# NSUC1602 register map
Vendor: ARM Ltd.; Series: NSUC1602; File version: 0.0
CPU: CM3 r1p0, little endian, MPU, no FPU, 3 interrupt priority bits
Registers are 32-bit, read-write, reset 0x0 unless marked. A register's access mark holds for its fields unless they carry their own. Offsets are from the block's base; [hi:lo] are bit positions; {n}, {i} and the like mark numbered series.

## GDU — S/T bus
Base 0x40000000
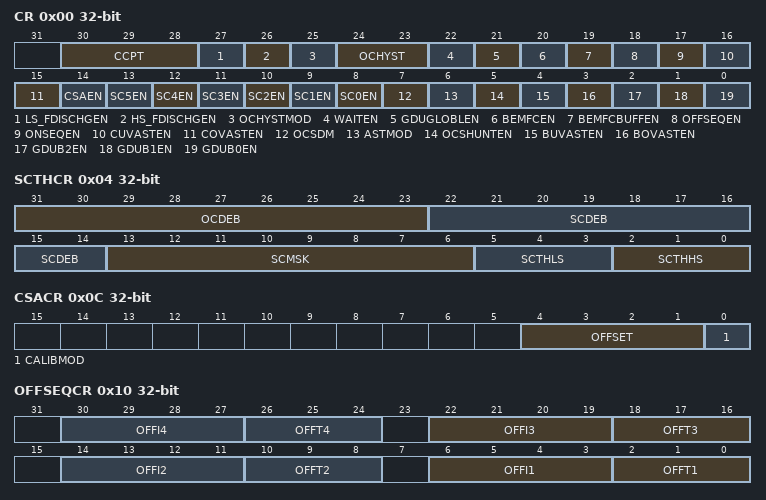
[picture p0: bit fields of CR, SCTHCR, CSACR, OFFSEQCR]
0x00 CR (reset mask 0x1337F7F) — GDU控制寄存器
  [30:28] CCPT, [27] LS_FDISCHGEN, [26] HS_FDISCHGEN, [25] OCHYSTMOD, [24:23] OCHYST, [22] WAITEN, [21] GDUGLOBLEN, [20] BEMFCEN, [19] BEMFCBUFFEN, [18] OFFSEQEN, [17] ONSEQEN, [16] CUVASTEN, [15] COVASTEN, [14] CSAEN, [n+8] SC{n}EN (n=0..5), [7] OCSDM, [6] ASTMOD, [5] OCSHUNTEN, [4] BUVASTEN, [3] BOVASTEN, [2] GDUB2EN, [1] GDUB1EN, [0] GDUB0EN
0x04 SCTHCR (reset mask 0x1337F7F) — VDS短路检测阈值以及滤波配置寄存器
  [31:23] OCDEB, [22:14] SCDEB, [13:6] SCMSK, [5:3] SCTHLS, [2:0] SCTHHS
0x08 GDUMUX — GDU mux寄存器
  [1:0] GPMUX
0x0C CSACR — Current Sense AMP寄存器
  [4:1] OFFSET, [0] CALIBMOD
0x10 OFFSEQCR (reset mask 0x1337F7F) — off slew rate 控制寄存器
  [8n-2:8n-5] OFFI{n} (n=1..4), [8n-6:8n-8] OFFT{n} (n=1..4)
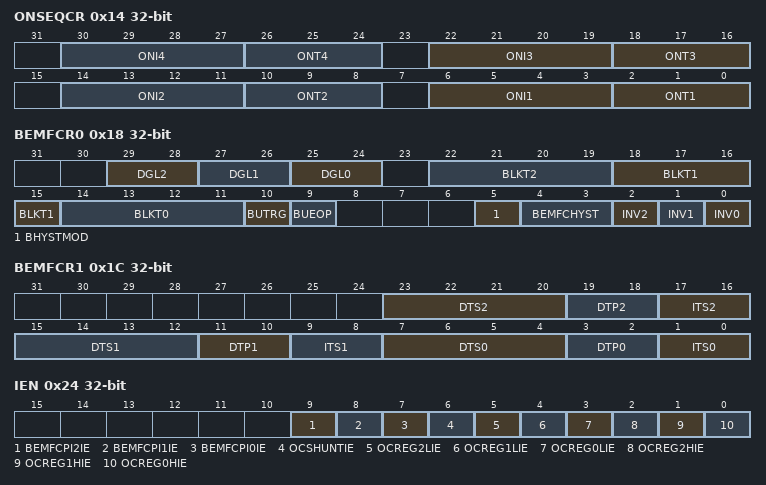
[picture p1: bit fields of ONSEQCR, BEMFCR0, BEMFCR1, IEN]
0x14 ONSEQCR (reset mask 0x1337F7F) — ON slew rate 控制寄存器
  [8n-2:8n-5] ONI{n} (n=1..4), [8n-6:8n-8] ONT{n} (n=1..4)
0x18 BEMFCR0 (reset mask 0x1337F7F) — bemfc控制寄存器0
  [29:28] DGL2, [27:26] DGL1, [25:24] DGL0, [22:19] BLKT2, [18:15] BLKT1, [14:11] BLKT0, [10] BUTRG, [9] BUEOP, [5] BHYSTMOD, [4:3] BEMFCHYST, [2] INV2, [1] INV1, [0] INV0
0x1C BEMFCR1 (reset mask 0x1337F7F) — bemfc控制寄存器1
  [23:20] DTS2, [19:18] DTP2, [17:16] ITS2, [15:12] DTS1, [11:10] DTP1, [9:8] ITS1, [7:4] DTS0, [3:2] DTP0, [1:0] ITS0
0x20 CLDAC (reset mask 0x1337F7F) — CLDAC寄存器
  [7:0] DATA
0x24 IEN (reset mask 0x1337F7F) — 中断使能寄存器
  [9] BEMFCPI2IE, [8] BEMFCPI1IE, [7] BEMFCPI0IE, [6] OCSHUNTIE, [5] OCREG2LIE, [4] OCREG1LIE, [3] OCREG0LIE, [2] OCREG2HIE, [1] OCREG1HIE, [0] OCREG0HIE
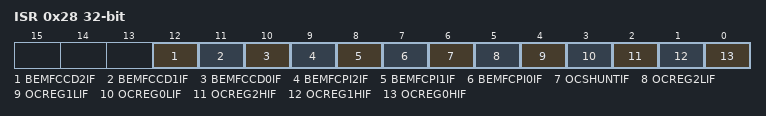
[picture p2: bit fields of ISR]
0x28 ISR (reset mask 0x1337F7F) — 中断状态寄存器
  [12] BEMFCCD2IF, [11] BEMFCCD1IF, [10] BEMFCCD0IF, [9] BEMFCPI2IF, [8] BEMFCPI1IF, [7] BEMFCPI0IF, [6] OCSHUNTIF, [5] OCREG2LIF, [4] OCREG1LIF, [3] OCREG0LIF, [2] OCREG2HIF, [1] OCREG1HIF, [0] OCREG0HIF

## SPI — S/T bus
Base 0x40001000
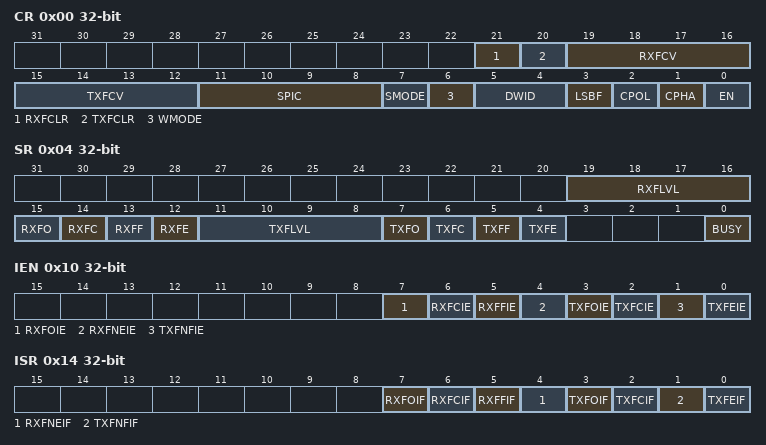
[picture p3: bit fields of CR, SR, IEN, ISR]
0x00 CR (reset mask 0x1337F7F) — SPI控制寄存器
  [21] RXFCLR, [20] TXFCLR, [19:16] RXFCV, [15:12] TXFCV, [11:8] SPIC, [7] SMODE, [6] WMODE, [5:4] DWID, [3] LSBF, [2] CPOL, [1] CPHA, [0] EN
0x04 SR (reset mask 0x1337F7F) — SPI状态寄存器
  [19:16] RXFLVL ro, [15] RXFO ro, [14] RXFC ro, [13] RXFF ro, [12] RXFE ro, [11:8] TXFLVL ro, [7] TXFO ro, [6] TXFC ro, [5] TXFF ro, [4] TXFE ro, [0] BUSY ro
0x08 TXF (reset mask 0x1337F7F) — SPI TX FIFO数据寄存器
  [31:0] DATA
0x0C RXF (reset mask 0x1337F7F) — SPI RX FIFO数据寄存器
  [31:0] DATA ro
0x10 IEN (reset mask 0x1337F7F) — 中断使能寄存器
  [7] RXFOIE, [6] RXFCIE, [5] RXFFIE, [4] RXFNEIE, [3] TXFOIE, [2] TXFCIE, [1] TXFNFIE, [0] TXFEIE
0x14 ISR (reset mask 0x1337F7F) — 中断使能置起寄存器
  [7] RXFOIF, [6] RXFCIF, [5] RXFFIF, [4] RXFNEIF, [3] TXFOIF, [2] TXFCIF, [1] TXFNFIF, [0] TXFEIF

## LINPORT — S/T bus
Base 0x40002000
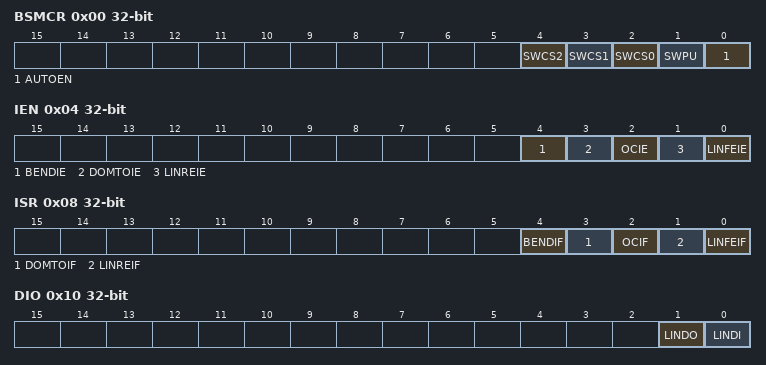
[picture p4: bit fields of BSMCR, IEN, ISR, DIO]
0x00 BSMCR — BSM控制寄存器
  [4] SWCS2, [3] SWCS1, [2] SWCS0, [1] SWPU, [0] AUTOEN
0x04 IEN — 中断使能寄存器
  [4] BENDIE, [3] DOMTOIE, [2] OCIE, [1] LINREIE, [0] LINFEIE
0x08 ISR — 软件触发中断寄存器
  [4] BENDIF, [3] DOMTOIF, [2] OCIF, [1] LINREIF, [0] LINFEIF
0x10 DIO — 数据寄存器
  [1] LINDO, [0] LINDI ro
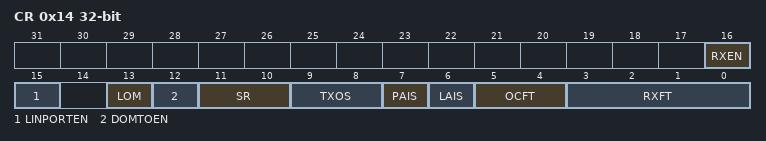
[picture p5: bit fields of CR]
0x14 CR (reset mask 0x1337F7F) — 控制寄存器
  [16] RXEN, [15] LINPORTEN, [13] LOM, [12] DOMTOEN, [11:10] SR, [9:8] TXOS, [7] PAIS, [6] LAIS, [5:4] OCFT, [3:0] RXFT
0x18 TIMEOUT (reset mask 0x1337F7F) — LIN TX 超时寄存器
  [21:0] TIMEOUT

## LINUART — S/T bus
Base 0x40003000
Same registers: UART1 0x40009000
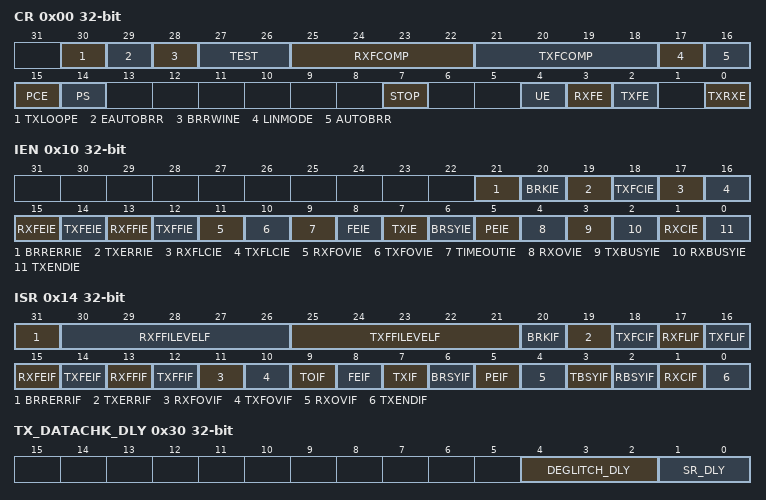
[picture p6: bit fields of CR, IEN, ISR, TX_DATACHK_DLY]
0x00 CR (reset mask 0x1337F7F) — 控制寄存器
  [30] TXLOOPE, [29] EAUTOBRR, [28] BRRWINE, [27:26] TEST, [25:22] RXFCOMP, [21:18] TXFCOMP, [17] LINMODE, [16] AUTOBRR, [15] PCE, [14] PS, [7] STOP, [4] UE, [3] RXFE, [2] TXFE, [0] TXRXE
0x04 BRR (reset mask 0x1337F7F) — 波特率寄存器
  [19:0] BRR
0x08 RDATA (reset mask 0x1337F7F) — 接收数据寄存器
  [8:0] RDATA ro
0x0C TDATA (reset mask 0x1337F7F) — 发送数据寄存器
  [8:0] TDATA
0x10 IEN (reset mask 0x1337F7F) — 中断使能寄存器
  [21] BRRERRIE, [20] BRKIE, [19] TXERRIE, [18] TXFCIE, [17] RXFLCIE, [16] TXFLCIE, [15] RXFEIE, [14] TXFEIE, [13] RXFFIE, [12] TXFFIE, [11] RXFOVIE, [10] TXFOVIE, [9] TIMEOUTIE, [8] FEIE, [7] TXIE, [6] BRSYIE, [5] PEIE, [4] RXOVIE, [3] TXBUSYIE, [2] RXBUSYIE, [1] RXCIE, [0] TXENDIE
0x14 ISR (reset mask 0x1337F7F) — 中断状态寄存器
  [31] BRRERRIF, [30:26] RXFFILEVELF ro, [25:21] TXFFILEVELF ro, [20] BRKIF, [19] TXERRIF, [18] TXFCIF, [17] RXFLIF, [16] TXFLIF, [15] RXFEIF, [14] TXFEIF, [13] RXFFIF, [12] TXFFIF, [11] RXFOVIF, [10] TXFOVIF, [9] TOIF, [8] FEIF, [7] TXIF, [6] BRSYIF, [5] PEIF, [4] RXOVIF, [3] TBSYIF ro, [2] RBSYIF ro, [1] RXCIF, [0] TXENDIF
0x18 RXFIFO (reset mask 0x1337F7F) — 接收FIFO数据寄存器
  [8:0] RXFIFO
0x1C TXFIFO (reset mask 0x1337F7F) — 发送FIFO数据寄存器
  [8:0] TXFIFO
0x20 TIMEOUT (reset mask 0x1337F7F) — LIN RX 超时寄存器
  [21:0] TIMEOUT
0x28 WINDW_MIN (reset mask 0x1337F7F)
  [19:0] WINDW_MIN
0x2C WINDW_MAX (reset mask 0x1337F7F)
  [19:0] WINDW_MAX
0x30 TX_DATACHK_DLY
  [4:2] DEGLITCH_DLY, [1:0] SR_DLY
